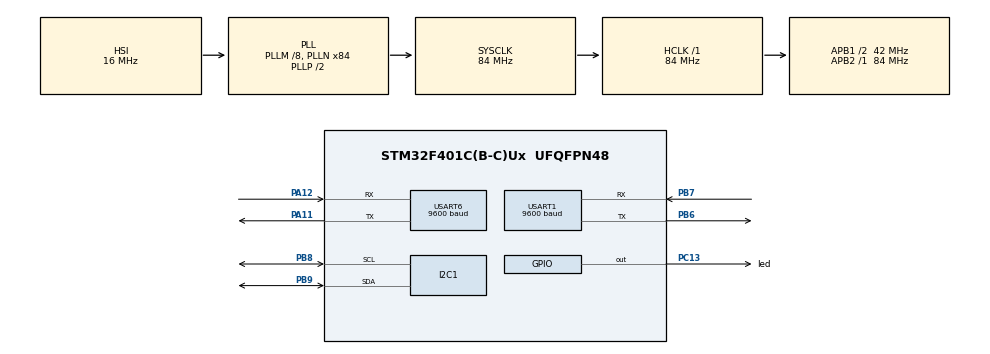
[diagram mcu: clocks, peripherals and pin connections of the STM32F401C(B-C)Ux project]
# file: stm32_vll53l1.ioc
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Dma.Request0=USART1_RX
Dma.Request1=USART1_TX
Dma.Request2=USART6_RX
Dma.Request3=USART6_TX
Dma.USART1_RX.0.Direction=DMA_PERIPH_TO_MEMORY
Dma.USART1_RX.0.FIFOMode=DMA_FIFOMODE_DISABLE
Dma.USART1_RX.0.Instance=DMA2_Stream2
Dma.USART1_RX.0.MemDataAlignment=DMA_MDATAALIGN_BYTE
Dma.USART1_RX.0.MemInc=DMA_MINC_ENABLE
Dma.USART1_RX.0.Mode=DMA_NORMAL
Dma.USART1_RX.0.PeriphDataAlignment=DMA_PDATAALIGN_BYTE
Dma.USART1_RX.0.PeriphInc=DMA_PINC_DISABLE
Dma.USART1_RX.0.Priority=DMA_PRIORITY_LOW
Dma.USART1_TX.1.Direction=DMA_MEMORY_TO_PERIPH
Dma.USART1_TX.1.FIFOMode=DMA_FIFOMODE_DISABLE
Dma.USART1_TX.1.Instance=DMA2_Stream7
Dma.USART1_TX.1.MemDataAlignment=DMA_MDATAALIGN_BYTE
Dma.USART1_TX.1.MemInc=DMA_MINC_ENABLE
Dma.USART1_TX.1.Mode=DMA_NORMAL
Dma.USART1_TX.1.PeriphDataAlignment=DMA_PDATAALIGN_BYTE
Dma.USART1_TX.1.PeriphInc=DMA_PINC_DISABLE
Dma.USART1_TX.1.Priority=DMA_PRIORITY_LOW
Dma.USART6_RX.2.Direction=DMA_PERIPH_TO_MEMORY
Dma.USART6_RX.2.FIFOMode=DMA_FIFOMODE_DISABLE
Dma.USART6_RX.2.Instance=DMA2_Stream1
Dma.USART6_RX.2.MemDataAlignment=DMA_MDATAALIGN_BYTE
Dma.USART6_RX.2.MemInc=DMA_MINC_ENABLE
Dma.USART6_RX.2.Mode=DMA_NORMAL
Dma.USART6_RX.2.PeriphDataAlignment=DMA_PDATAALIGN_BYTE
Dma.USART6_RX.2.PeriphInc=DMA_PINC_DISABLE
Dma.USART6_RX.2.Priority=DMA_PRIORITY_LOW
Dma.USART6_TX.3.Direction=DMA_MEMORY_TO_PERIPH
Dma.USART6_TX.3.FIFOMode=DMA_FIFOMODE_DISABLE
Dma.USART6_TX.3.Instance=DMA2_Stream6
Dma.USART6_TX.3.MemDataAlignment=DMA_MDATAALIGN_BYTE
Dma.USART6_TX.3.MemInc=DMA_MINC_ENABLE
Dma.USART6_TX.3.Mode=DMA_NORMAL
Dma.USART6_TX.3.PeriphDataAlignment=DMA_PDATAALIGN_BYTE
Dma.USART6_TX.3.PeriphInc=DMA_PINC_DISABLE
Dma.USART6_TX.3.Priority=DMA_PRIORITY_LOW
Mcu.Family=STM32F4
Mcu.Name=STM32F401C(B-C)Ux
Mcu.Package=UFQFPN48
NVIC.DMA2_Stream1_IRQn=true\:0\:0\:false\:false\:true\:false\:true\:true
NVIC.DMA2_Stream2_IRQn=true\:0\:0\:false\:false\:true\:false\:true\:true
NVIC.DMA2_Stream6_IRQn=true\:0\:0\:false\:false\:true\:false\:true\:true
NVIC.DMA2_Stream7_IRQn=true\:0\:0\:false\:false\:true\:false\:true\:true
NVIC.PriorityGroup=NVIC_PRIORITYGROUP_4
NVIC.USART1_IRQn=true\:0\:0\:false\:false\:true\:false\:true\:true
NVIC.USART6_IRQn=true\:0\:0\:false\:false\:true\:false\:true\:true
PA11.Mode=Asynchronous
PA11.Signal=USART6_TX
PA12.Mode=Asynchronous
PA12.Signal=USART6_RX
PB6.Mode=Asynchronous
PB6.Signal=USART1_TX
PB7.Mode=Asynchronous
PB7.Signal=USART1_RX
PB8.Mode=I2C
PB8.Signal=I2C1_SCL
PB9.Mode=I2C
PB9.Signal=I2C1_SDA
PC13-ANTI_TAMP.GPIO_Label=led
PC13-ANTI_TAMP.Signal=GPIO_Output
PH0\ -\ OSC_IN.Mode=HSE-External-Oscillator
PH0\ -\ OSC_IN.Signal=RCC_OSC_IN
PH1\ -\ OSC_OUT.Mode=HSE-External-Oscillator
PH1\ -\ OSC_OUT.Signal=RCC_OSC_OUT
ProjectManager.HeapSize=0x200
ProjectManager.StackSize=0x400
ProjectManager.TargetToolchain=STM32CubeIDE
RCC.48MHZClocksFreq_Value=42000000
RCC.AHBFreq_Value=84000000
RCC.APB1CLKDivider=RCC_HCLK_DIV2
RCC.APB1Freq_Value=42000000
RCC.APB1TimFreq_Value=84000000
RCC.APB2Freq_Value=84000000
RCC.APB2TimFreq_Value=84000000
RCC.CortexFreq_Value=84000000
RCC.HCLKFreq_Value=84000000
RCC.HSE_VALUE=25000000
RCC.HSI_VALUE=16000000
RCC.LSE_VALUE=32768
RCC.PLLM=8
RCC.PLLN=84
RCC.SYSCLKFreq_VALUE=84000000
RCC.SYSCLKSource=RCC_SYSCLKSOURCE_PLLCLK
RCC.VCOOutputFreq_Value=168000000
USART1.BaudRate=9600
USART1.Parity=PARITY_NONE
USART1.VirtualMode=VM_ASYNC
USART6.BaudRate=9600
USART6.Parity=PARITY_EVEN
USART6.VirtualMode=VM_ASYNC
board=custom

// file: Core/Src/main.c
/* USER CODE BEGIN Header */
/**
  ******************************************************************************
  * @file           : main.c
  * @brief          : Main program body
  ******************************************************************************
  * @attention
  *
  * Copyright (c) 2026 STMicroelectronics.
  * All rights reserved.
  *
  * This software is licensed under terms that can be found in the LICENSE file
  * in the root directory of this software component.
  * If no LICENSE file comes with this software, it is provided AS-IS.
  *
  ******************************************************************************
  */
/* USER CODE END Header */
#include "main.h"
#include "dma.h"
#include "i2c.h"
#include "usart.h"
#include "gpio.h"

/* USER CODE BEGIN Includes */
#include "vl53l1x_mitsu_app.h"
/* USER CODE END Includes */

void SystemClock_Config(void);

int main(void)
{

  /* MCU Configuration--------------------------------------------------------*/

  /* Reset of all peripherals, Initializes the Flash interface and the Systick. */
  HAL_Init();

  /* Configure the system clock */
  SystemClock_Config();

  /* Initialize all configured peripherals */
  MX_GPIO_Init();
  MX_DMA_Init();
  MX_I2C1_Init();
  MX_USART1_UART_Init();
  MX_USART6_UART_Init();
  /* USER CODE BEGIN 2 */
  VL53L1X_App_Init();
  /* USER CODE END 2 */

  /* Infinite loop */
  /* USER CODE BEGIN WHILE */
  while (1)
  {
    VL53L1X_App_Process();
    /* USER CODE END WHILE */

  }
}

void SystemClock_Config(void)
{
  RCC_OscInitTypeDef RCC_OscInitStruct = {0};
  RCC_ClkInitTypeDef RCC_ClkInitStruct = {0};

  /** Configure the main internal regulator output voltage
  */
  __HAL_RCC_PWR_CLK_ENABLE();
  __HAL_PWR_VOLTAGESCALING_CONFIG(PWR_REGULATOR_VOLTAGE_SCALE2);

  /** Initializes the RCC Oscillators according to the specified parameters
  * in the RCC_OscInitTypeDef structure.
  */
  RCC_OscInitStruct.OscillatorType = RCC_OSCILLATORTYPE_HSI;
  RCC_OscInitStruct.HSIState = RCC_HSI_ON;
  RCC_OscInitStruct.HSICalibrationValue = RCC_HSICALIBRATION_DEFAULT;
  RCC_OscInitStruct.PLL.PLLState = RCC_PLL_ON;
  RCC_OscInitStruct.PLL.PLLSource = RCC_PLLSOURCE_HSI;
  RCC_OscInitStruct.PLL.PLLM = 8;
  RCC_OscInitStruct.PLL.PLLN = 84;
  RCC_OscInitStruct.PLL.PLLP = RCC_PLLP_DIV2;
  RCC_OscInitStruct.PLL.PLLQ = 4;
  if (HAL_RCC_OscConfig(&RCC_OscInitStruct) != HAL_OK)
  {
    Error_Handler();
  }

  /** Initializes the CPU, AHB and APB buses clocks
  */
  RCC_ClkInitStruct.ClockType = RCC_CLOCKTYPE_HCLK|RCC_CLOCKTYPE_SYSCLK
                              |RCC_CLOCKTYPE_PCLK1|RCC_CLOCKTYPE_PCLK2;
  RCC_ClkInitStruct.SYSCLKSource = RCC_SYSCLKSOURCE_PLLCLK;
  RCC_ClkInitStruct.AHBCLKDivider = RCC_SYSCLK_DIV1;
  RCC_ClkInitStruct.APB1CLKDivider = RCC_HCLK_DIV2;
  RCC_ClkInitStruct.APB2CLKDivider = RCC_HCLK_DIV1;

  if (HAL_RCC_ClockConfig(&RCC_ClkInitStruct, FLASH_LATENCY_2) != HAL_OK)
  {
    Error_Handler();
  }
}

void Error_Handler(void)
{
  __disable_irq();
  while (1)
  {
  }
}
